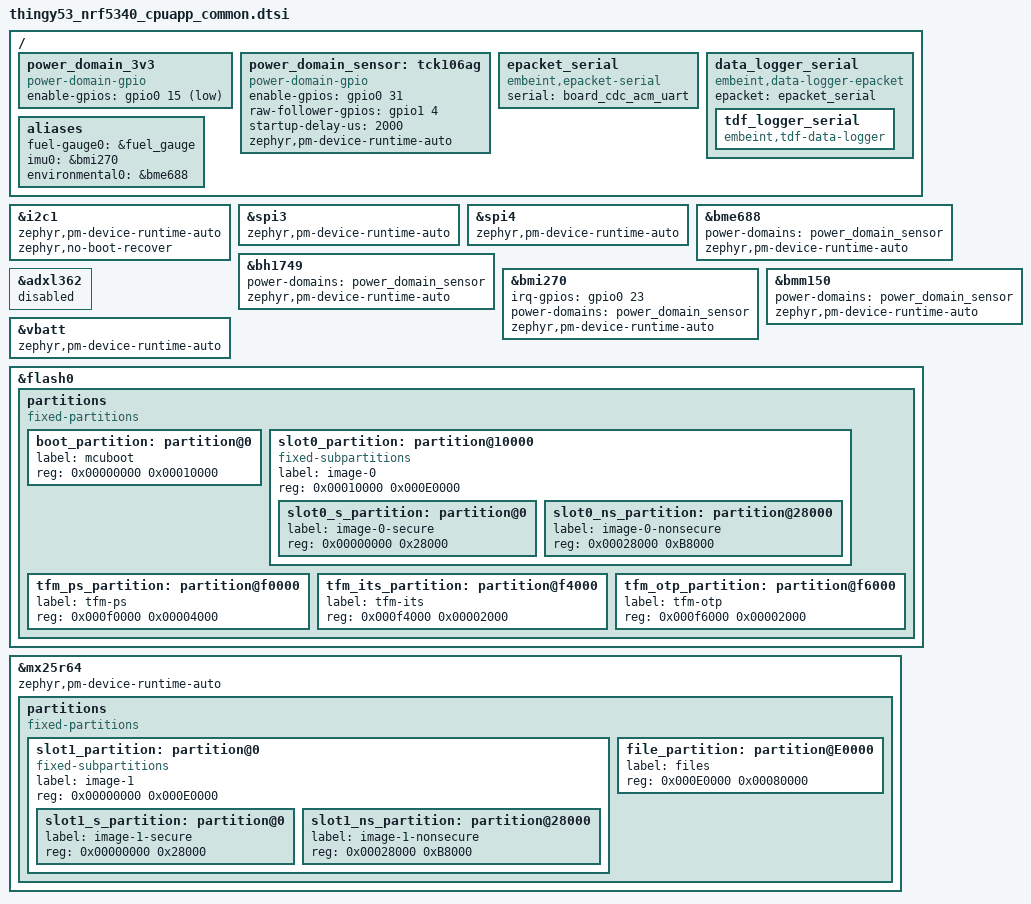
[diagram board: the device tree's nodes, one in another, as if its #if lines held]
#include <zephyr/dt-bindings/gpio/gpio.h>
#include <common/infuse_bluetooth.dtsi>

/* Dynamic power domains, not regulators that are always on */
/delete-node/ &regulator_3v3;
/delete-node/ &sensor_pwr_ctrl;

/ {
	power_domain_3v3: power_domain_3v3 {
		compatible = "power-domain-gpio";
		#power-domain-cells = <0>;
		enable-gpios = <&gpio0 15 GPIO_ACTIVE_LOW>;
		/* nRF7002 driver does not handle this power domain */
	};

	power_domain_sensor: tck106ag {
		compatible = "power-domain-gpio";
		#power-domain-cells = <0>;
		enable-gpios = <&gpio0 31 GPIO_ACTIVE_HIGH>;
		/* BMI270 CS pin needs to go low with the power domain */
		raw-follower-gpios = <&gpio1 4 GPIO_ACTIVE_HIGH>;
		/* 2ms delay for BME688 */
		startup-delay-us = <2000>;
		zephyr,pm-device-runtime-auto;
	};

	epacket_serial: epacket_serial {
		compatible = "embeint,epacket-serial";
		serial = <&board_cdc_acm_uart>;
	};

	data_logger_serial: data_logger_serial {
		compatible = "embeint,data-logger-epacket", "embeint,data-logger";
		epacket = <&epacket_serial>;

		tdf_logger_serial: tdf_logger_serial {
			compatible = "embeint,tdf-data-logger";
		};
	};

	data_logger_flash: data_logger_flash {
		compatible = "embeint,data-logger-flash-map", "embeint,data-logger";
		partition = <&data_logger_partition>;

		tdf_logger_flash: tdf_logger_flash {
			compatible = "embeint,tdf-data-logger";
		};
	};

	aliases {
		fuel-gauge0 = &fuel_gauge;
		imu0 = &bmi270;
		environmental0 = &bme688;
	};
};

&i2c1 {
	zephyr,pm-device-runtime-auto;
	zephyr,no-boot-recover;
};

&spi3 {
	zephyr,pm-device-runtime-auto;
};

&spi4 {
	zephyr,pm-device-runtime-auto;
};

&bme688 {
	power-domains = <&power_domain_sensor>;
	zephyr,pm-device-runtime-auto;
};

&bh1749 {
	power-domains = <&power_domain_sensor>;
	zephyr,pm-device-runtime-auto;
};

&bmi270 {
	status = "okay";
	irq-gpios = <&gpio0 23 GPIO_ACTIVE_HIGH>;
	power-domains = <&power_domain_sensor>;
	zephyr,pm-device-runtime-auto;
};

&bmm150 {
	power-domains = <&power_domain_sensor>;
	zephyr,pm-device-runtime-auto;
};

&adxl362 {
	status = "disabled";
};

&vbatt {
	zephyr,pm-device-runtime-auto;
};

/* MCUboot secondary on external flash */
/delete-node/ &slot0_partition;
/delete-node/ &slot1_partition;

&flash0 {
	partitions {
		compatible = "fixed-partitions";
		#address-cells = <1>;
		#size-cells = <1>;

		boot_partition: partition@0 {
			label = "mcuboot";
			reg = <0x00000000 0x00010000>;
		};
		slot0_partition: partition@10000 {
			compatible = "fixed-subpartitions";
			label = "image-0";
			reg = <0x00010000 0x000E0000>;
			ranges = <0x0 0x10000 0xE0000>;
			#address-cells = <1>;
			#size-cells = <1>;

			slot0_s_partition: partition@0 {
				label = "image-0-secure";
				reg = <0x00000000 0x28000>;
			};
			slot0_ns_partition: partition@28000 {
				label = "image-0-nonsecure";
				reg = <0x00028000 0xB8000>;
			};
		};
		tfm_ps_partition: partition@f0000 {
			label = "tfm-ps";
			reg = <0x000f0000 0x00004000>;
		};
		tfm_its_partition: partition@f4000 {
			label = "tfm-its";
			reg = <0x000f4000 0x00002000>;
		};
		tfm_otp_partition: partition@f6000 {
			label = "tfm-otp";
			reg = <0x000f6000 0x00002000>;
		};
	};
};

&mx25r64 {
	zephyr,pm-device-runtime-auto;

	partitions {
		compatible = "fixed-partitions";
		#address-cells = <1>;
		#size-cells = <1>;

		slot1_partition: partition@0 {
			compatible = "fixed-subpartitions";
			label = "image-1";
			reg = <0x00000000 0x000E0000>;
			ranges = <0x0 0x0 0xE0000>;
			#address-cells = <1>;
			#size-cells = <1>;

			slot1_s_partition: partition@0 {
				label = "image-1-secure";
				reg = <0x00000000 0x28000>;
			};

			slot1_ns_partition: partition@28000 {
				label = "image-1-nonsecure";
				reg = <0x00028000 0xB8000>;
			};
		};
		file_partition: partition@E0000 {
			label = "files";
			reg = <0x000E0000 0x00080000>;
		};
		data_logger_partition: partition@160000 {
			label = "data_logger";
			reg = <0x00160000 0x0006A0000>;
		};
	};
};

#ifdef INFUSE_IS_BOOTLOADER

/* Bootloader doesn't know about external flash */
/delete-node/ &data_logger_flash;
/delete-node/ &data_logger_partition;

#endif /* INFUSE_IS_BOOTLOADER */
